# SWM181 register map
File version: 1.0
SWM181 Microcontroller registers
CPU: CM0 r1p0, little endian, 2 interrupt priority bits
Registers are 32-bit, read-write, no defined reset value unless marked. A register's access mark holds for its fields unless they carry their own. Offsets are from the block's base; lines under a group give offsets from that group; [hi:lo] are bit positions; {n}, {i} and the like mark numbered series; 'fields as' and 'values as' point back to an identical list; <NAME> marks a mode.

## Memory map
0x40000000 SYS size 0x1000C0E4 — Registers group
0x41000000 DMA size 0x58 — Registers group
0x43000000 CACHE size 0x74 — Registers group
0x44000000 FLASH size 0x48 — Registers group
0x45000000 IRQMUX size 0x314 — Registers group
0x46000000 DIV size 0x28 — Registers group
0x47000000 CORDIC size 0x1C — Registers group
0x50000000 PORTG size 0x44 — Registers group
0x50000100 PORTA size 0x504 — Registers group
0x50000110 PORTB size 0x504
0x50000120 PORTC size 0x504
0x50000130 PORTD size 0x504
0x50000140 PORTE size 0x504
0x50001000 GPIOA size 0x24 — Registers group
0x50002000 GPIOB size 0x24
0x50003000 GPIOC size 0x24
0x50004000 GPIOD size 0x24
0x50005000 GPIOE size 0x24
0x50007000 TIMR0 size 0xC — Registers group
0x5000700C TIMR1 size 0xC
0x50007018 TIMR2 size 0xC
0x50007024 TIMR3 size 0xC
0x50007060 TIMRG size 0x3C — Registers group
0x50009000 WDT size 0x14 — Registers group
0x5000A000 PWM0 size 0x20 — Registers group
0x5000A020 PWM1 size 0x20
0x5000A040 PWM2 size 0x20
0x5000A060 PWM3 size 0x20
0x5000A170 PWMG size 0x68 — Registers group
0x5000D000 ADC size 0x98 — Registers group
0x50010000 UART0 size 0x1C — Registers group
0x50011000 UART1 size 0x1C
0x50012000 UART2 size 0x1C
0x50013000 UART3 size 0x1C
0x50018000 I2C0 size 0x34 — Registers group
0x50019000 I2C1 size 0x34
0x5001C000 SPI0 size 0x14 — Registers group
0x5001D000 SPI1 size 0x14
0x50020000 CAN size 0x1B4 — Registers group
0x50040000 SDADC size 0x48 — Registers group
0x50050000 SLCD size 0x20 — Registers group

## SYS — Registers group
Base 0x40000000
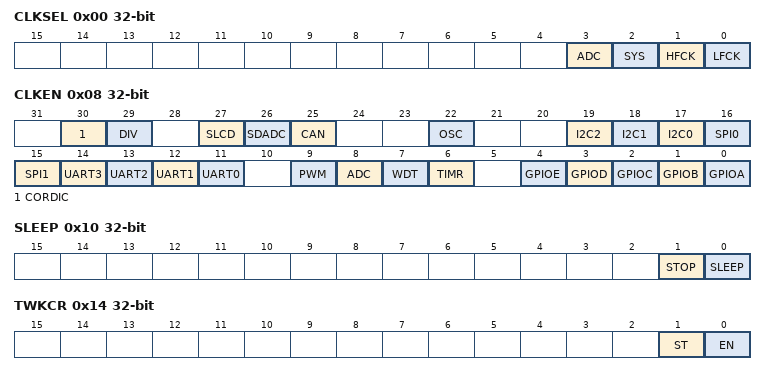
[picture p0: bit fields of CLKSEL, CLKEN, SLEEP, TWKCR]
0x00 CLKSEL
  [3] ADC, [2] SYS, [1] HFCK, [0] LFCK
0x08 CLKEN
  [30] CORDIC, [29] DIV, [27] SLCD, [26] SDADC, [25] CAN, [22] OSC, [19] I2C2, [18] I2C1, [17] I2C0, [16] SPI0, [15] SPI1, [n+11] UART{n} (n=0..3), [9] PWM, [8] ADC, [7] WDT, [6] TIMR, [4] GPIOE, [3] GPIOD, [2] GPIOC, [1] GPIOB, [0] GPIOA
0x10 SLEEP
  [1] STOP, [0] SLEEP
0x14 TWKCR
  [1] ST, [0] EN
0x18 TWKTIM
{0x100+4i} CHIP_ID[{i}] (i=0..3)
0x200 PAWKEN
0x204 PBWKEN
0x208 PCWKEN
0x20C PDWKEN
0x210 PEWKEN
0x218 PAWKSR
0x21C PBWKSR
0x220 PCWKSR
0x224 PDWKSR
0x228 PEWKSR
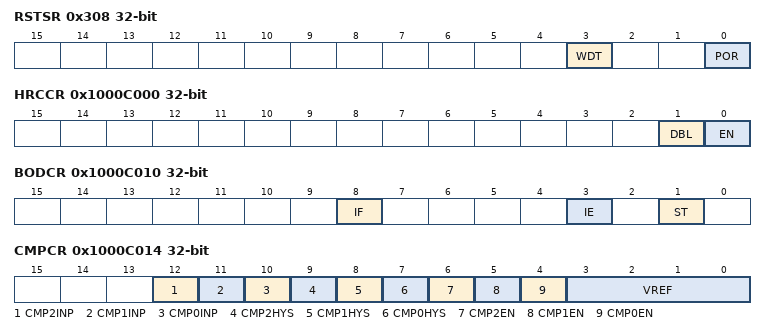
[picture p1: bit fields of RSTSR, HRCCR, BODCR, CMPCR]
0x308 RSTSR
  [3] WDT, [0] POR
0x400 CACHECR
  [0] BYPASS
0x1000C000 HRCCR
  [1] DBL, [0] EN
0x1000C010 BODCR
  [8] IF, [3] IE, [1] ST
0x1000C014 CMPCR
  [12] CMP2INP, [11] CMP1INP, [10] CMP0INP, [9] CMP2HYS, [8] CMP1HYS, [7] CMP0HYS, [6] CMP2EN, [5] CMP1EN, [4] CMP0EN, [3:0] VREF
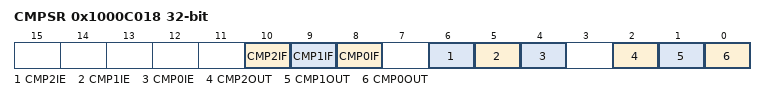
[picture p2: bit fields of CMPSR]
0x1000C018 CMPSR
  [10] CMP2IF, [9] CMP1IF, [8] CMP0IF, [6] CMP2IE, [5] CMP1IE, [4] CMP0IE, [2] CMP2OUT, [1] CMP1OUT, [0] CMP0OUT
0x1000C01C XTALCR
  [1] EN
0x1000C020 LRCCR
  [0] EN
0x1000C0E0 TESTANA

## IRQMUX — Registers group
Base 0x45000000
{0x0+4i} IRQ{i}_SRC (i=0..15)
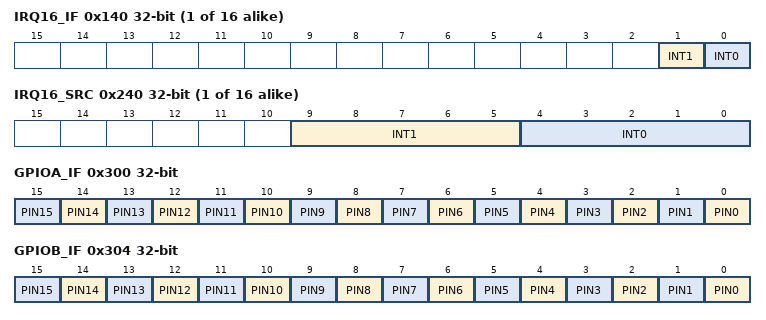
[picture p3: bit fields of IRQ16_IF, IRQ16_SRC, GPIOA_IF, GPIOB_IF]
{0x100+4i} IRQ{i}_IF (i=16..31)
  [1] INT1, [0] INT0
{0x200+4i} IRQ{i}_SRC (i=16..31)
  [9:5] INT1, [4:0] INT0
0x300 GPIOA_IF
  [n] PIN{n} (n=0..15)
0x304 GPIOB_IF
  [n] PIN{n} (n=0..15)
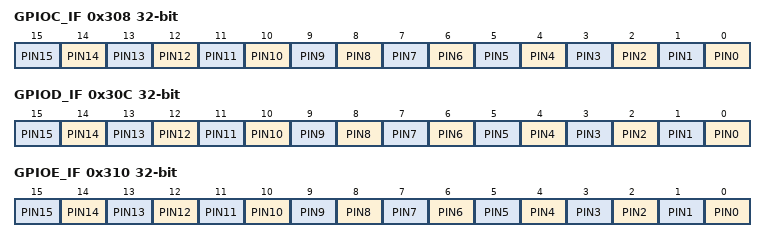
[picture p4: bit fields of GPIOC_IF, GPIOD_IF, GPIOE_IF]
0x308 GPIOC_IF
  [n] PIN{n} (n=0..15)
0x30C GPIOD_IF
  [n] PIN{n} (n=0..15)
0x310 GPIOE_IF
  [n] PIN{n} (n=0..15)

## CACHE — Registers group
Base 0x43000000
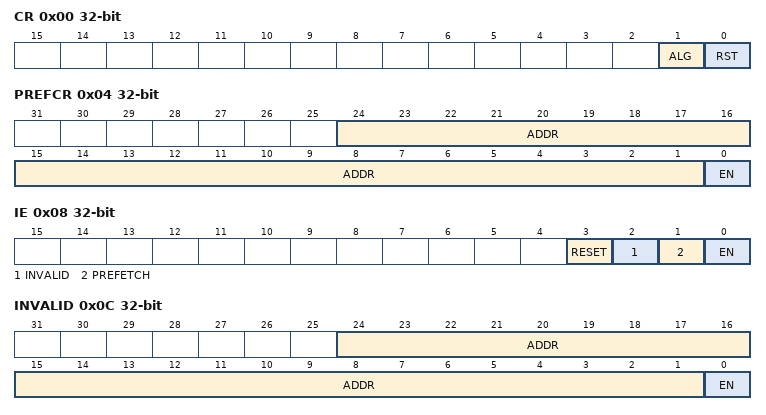
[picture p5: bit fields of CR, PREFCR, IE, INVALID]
0x00 CR
  [1] ALG, [0] RST
0x04 PREFCR
  [24:1] ADDR, [0] EN
0x08 IE
  [3] RESET, [2] INVALID, [1] PREFETCH, [0] EN
0x0C INVALID
  [24:1] ADDR, [0] EN
0x10 LOCKTHR
0x14 LOCKCNT ro
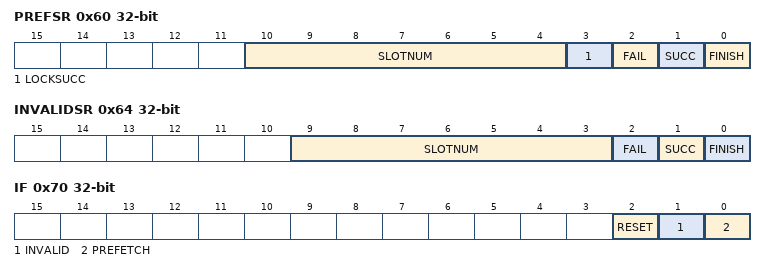
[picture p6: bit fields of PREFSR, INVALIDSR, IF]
0x60 PREFSR
  [10:4] SLOTNUM, [3] LOCKSUCC, [2] FAIL, [1] SUCC, [0] FINISH
0x64 INVALIDSR
  [9:3] SLOTNUM, [2] FAIL, [1] SUCC, [0] FINISH
0x68 ACCESSCNT
0x6C HITCNT
0x70 IF
  [2] RESET, [1] INVALID, [0] PREFETCH

## FLASH — Registers group
Base 0x44000000
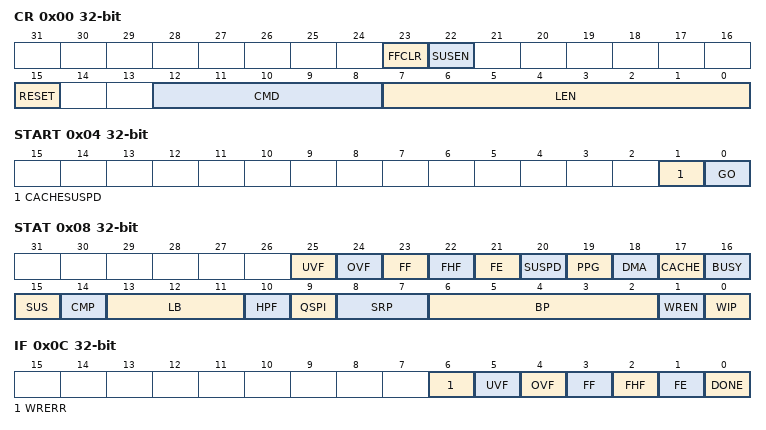
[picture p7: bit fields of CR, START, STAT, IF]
0x00 CR
  [23] FFCLR, [22] SUSEN, [15] RESET, [12:8] CMD, [7:0] LEN
0x04 START
  [1] CACHESUSPD, [0] GO
0x08 STAT
  [25] UVF, [24] OVF, [23] FF, [22] FHF, [21] FE, [20] SUSPD, [19] PPG, [18] DMA, [17] CACHE, [16] BUSY, [15] SUS, [14] CMP, [13:11] LB, [10] HPF, [9] QSPI, [8:7] SRP, [6:2] BP, [1] WREN, [0] WIP
0x0C IF
  [6] WRERR, [5] UVF, [4] OVF, [3] FF, [2] FHF, [1] FE, [0] DONE
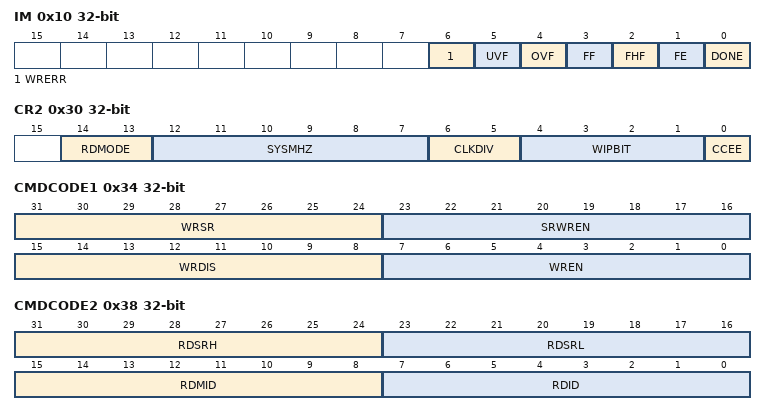
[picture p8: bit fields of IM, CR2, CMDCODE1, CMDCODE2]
0x10 IM
  [6] WRERR, [5] UVF, [4] OVF, [3] FF, [2] FHF, [1] FE, [0] DONE
0x14 ADDR
0x18 DATA
0x30 CR2
  [14:13] RDMODE, [12:7] SYSMHZ, [6:5] CLKDIV, [4:1] WIPBIT, [0] CCEE
0x34 CMDCODE1
  [31:24] WRSR, [23:16] SRWREN, [15:8] WRDIS, [7:0] WREN
0x38 CMDCODE2
  [31:24] RDSRH, [23:16] RDSRL, [15:8] RDMID, [7:0] RDID
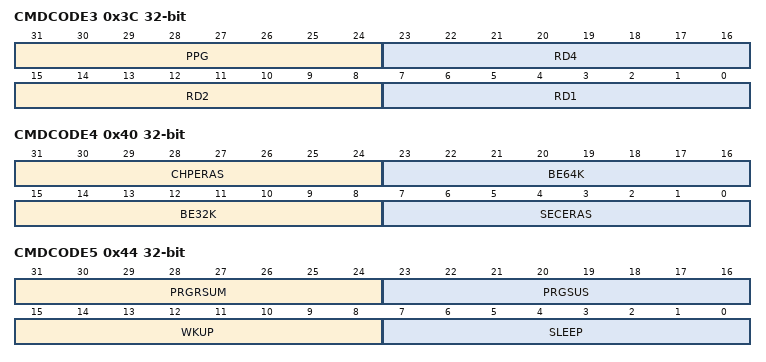
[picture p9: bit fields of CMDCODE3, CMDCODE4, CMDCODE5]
0x3C CMDCODE3
  [31:24] PPG, [23:16] RD4, [15:8] RD2, [7:0] RD1
0x40 CMDCODE4
  [31:24] CHPERAS, [23:16] BE64K, [15:8] BE32K, [7:0] SECERAS
0x44 CMDCODE5
  [31:24] PRGRSUM, [23:16] PRGSUS, [15:8] WKUP, [7:0] SLEEP
